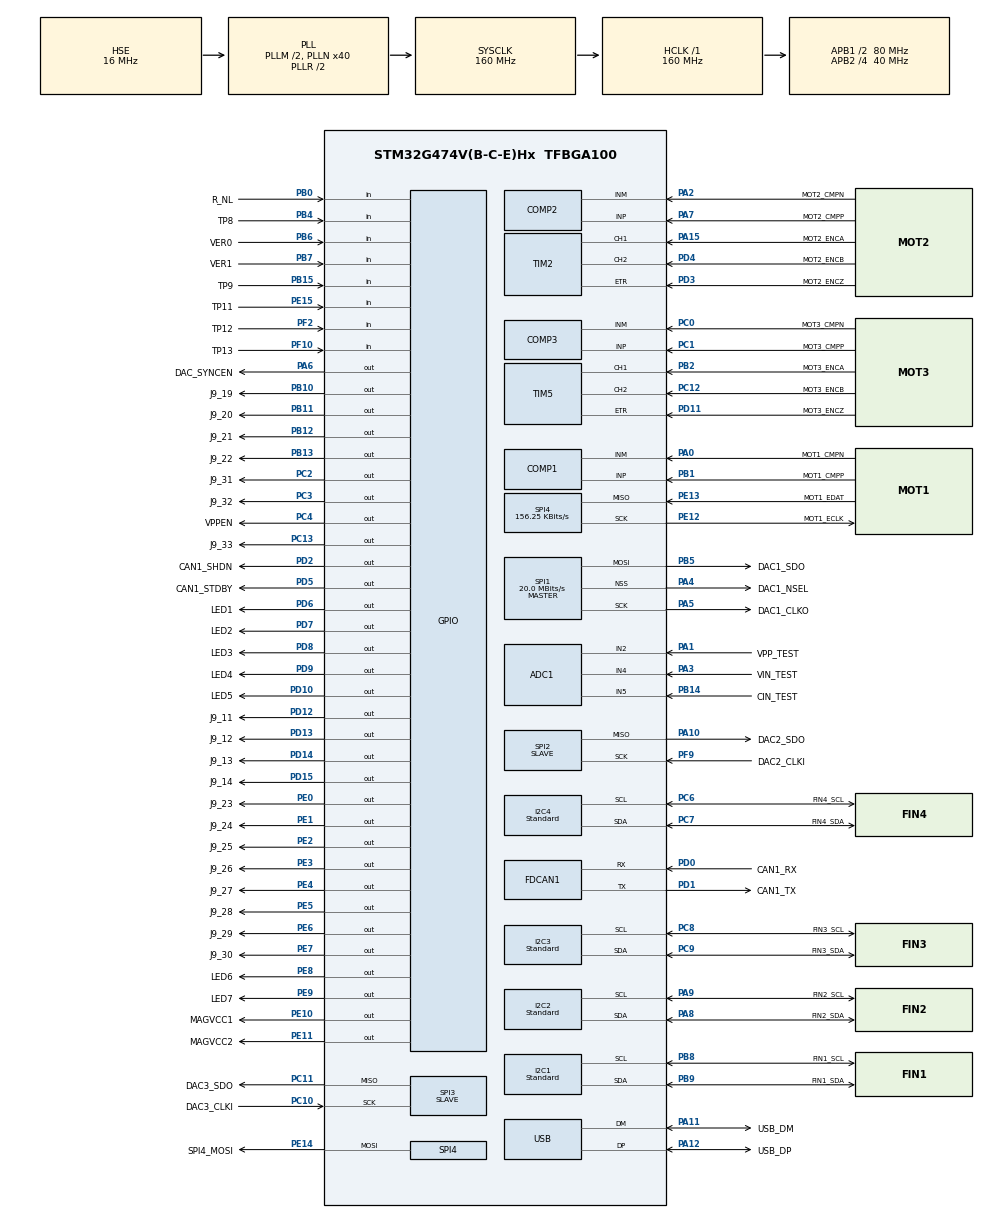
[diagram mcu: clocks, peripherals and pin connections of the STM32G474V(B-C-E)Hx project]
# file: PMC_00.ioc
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Dma.SPI3_TX.2.MemInc=DMA_MINC_ENABLE
Dma.I2C3_TX.8.PeriphInc=DMA_PINC_DISABLE
Dma.I2C2_TX.6.PeriphInc=DMA_PINC_DISABLE
PD12.GPIO_Label=J9_11
Dma.SPI1_TX.0.PeriphInc=DMA_PINC_DISABLE
NVIC.I2C1_EV_IRQn=true\:5\:0\:false\:false\:true\:true\:true\:true
VP_ADC1_TempSens_Input.Mode=IN-TempSens
Dma.I2C1_TX.4.PeriphInc=DMA_PINC_DISABLE
PA10.GPIO_PuPd=GPIO_PULLUP
COMP1.Hysteresis=COMP_HYSTERESIS_10MV
PF10.GPIO_PuPd=GPIO_PULLDOWN
ADC1.SamplingTime-12\#ChannelRegularConversion=ADC_SAMPLETIME_640CYCLES_5
NVIC.I2C4_EV_IRQn=true\:5\:0\:false\:false\:true\:true\:true\:true
NVIC.DMA1_Channel3_IRQn=true\:5\:0\:false\:false\:true\:false\:false\:true
FREERTOS.configENABLE_FPU=1
FREERTOS.INCLUDE_pcTaskGetTaskName=1
ADC1.Channel-5\#ChannelRegularConversion=ADC_CHANNEL_5
PA4.Mode=NSS_Signal_Hard_Output
Dma.I2C3_RX.7.Priority=DMA_PRIORITY_LOW
ADC1.Rank-11\#ChannelRegularConversion=11
SPI1.Direction=SPI_DIRECTION_2LINES
Dma.I2C2_RX.5.Polarity=HAL_DMAMUX_REQ_GEN_RISING
Dma.ADC1.11.Priority=DMA_PRIORITY_HIGH
I2C2.I2C_Speed_Mode=I2C_Standard
RCC.APB2TimFreq_Value=80000000
Dma.SPI3_TX.2.PeriphDataAlignment=DMA_PDATAALIGN_HALFWORD
PB6.Signal=GPIO_Input
Dma.I2C2_RX.5.SyncRequestNumber=1
PC7.Signal=I2C4_SDA
SPI1.CalculateBaudRate=20.0 MBits/s
PD0.Signal=FDCAN1_RX
PD8.Signal=GPIO_Output
PE1.Signal=GPIO_Output
FREERTOS.configMINIMAL_STACK_SIZE=512
Dma.I2C1_RX.3.Mode=DMA_NORMAL
VREF+.Signal=VREFBUF_OUT
PB3.Mode=Trace_Asynchronous_SW
RCC.ADC12Freq_Value=160000000
RCC.RTCClockSelection=RCC_RTCCLKSOURCE_LSE
PD1.GPIO_Label=CAN1_TX
PB12.GPIO_Label=J9_21
Dma.I2C2_TX.6.Mode=DMA_NORMAL
Dma.I2C3_TX.8.MemInc=DMA_MINC_ENABLE
PC4.GPIO_Label=VPPEN
Dma.I2C2_TX.6.Instance=DMA1_Channel7
PD1.GPIO_Speed=GPIO_SPEED_FREQ_VERY_HIGH
PE9.Signal=GPIO_Output
NVIC.DMA2_Channel4_IRQn=true\:5\:0\:false\:false\:true\:true\:false\:true
PB14.Mode=IN5-Single-Ended
PB1.GPIO_Label=MOT1_CMPP
NVIC.TIM2_IRQn=true\:5\:0\:false\:false\:true\:false\:true\:true
SPI1.DataSize=SPI_DATASIZE_16BIT
PE4.GPIO_Label=J9_27
PC9.Mode=I2C
PA8.Signal=I2C2_SDA
PE13.Mode=Full_Duplex_Master
Dma.SPI1_TX.0.RequestNumber=1
NVIC.DMA2_Channel3_IRQn=true\:5\:0\:false\:false\:true\:false\:false\:true
Dma.I2C4_TX.10.Instance=DMA2_Channel3
Dma.ADC1.11.PeriphInc=DMA_PINC_DISABLE
Dma.SPI3_TX.2.Direction=DMA_MEMORY_TO_PERIPH
Dma.SPI1_TX.0.Polarity=HAL_DMAMUX_REQ_GEN_RISING
Dma.I2C3_TX.8.SyncSignalID=NONE
PA0.Signal=COMP1_INM
Dma.I2C4_RX.9.PeriphDataAlignment=DMA_PDATAALIGN_BYTE
Dma.SPI1_TX.0.Mode=DMA_CIRCULAR
ADC1.OffsetNumber-5\#ChannelRegularConversion=ADC_OFFSET_NONE
Mcu.Package=TFBGA100
PB9.Signal=I2C1_SDA
PB1.Signal=COMP1_INP
SPI2.Mode=SPI_MODE_SLAVE
Dma.I2C1_RX.3.SignalID=NONE
SPI3.Mode=SPI_MODE_SLAVE
PD12.Signal=GPIO_Output
PA10.Signal=SPI2_MISO
VP_RTC_VS_RTC_Calendar.Mode=RTC_Calendar
PE12.GPIO_Label=MOT1_ECLK
Dma.ADC1.11.SyncSignalID=NONE
Dma.SPI2_TX.1.Instance=DMA1_Channel2
PC11.Mode=TX_Only_Simplex_Unidirect_Slave
PC8.GPIO_Speed=GPIO_SPEED_FREQ_VERY_HIGH
PE12.GPIO_Speed=GPIO_SPEED_FREQ_VERY_HIGH
Dma.I2C3_RX.7.MemInc=DMA_MINC_ENABLE
PB5.GPIO_Speed=GPIO_SPEED_FREQ_VERY_HIGH
Dma.ADC1.11.SyncEnable=DISABLE
PE8.GPIO_Speed=GPIO_SPEED_FREQ_HIGH
RCC.APB2CLKDivider=RCC_HCLK_DIV4
FDCAN1.DataTimeSeg2=5
FDCAN1.DataTimeSeg1=3
RCC.APB1TimFreq_Value=160000000
PD5.GPIO_Speed=GPIO_SPEED_FREQ_HIGH
NVIC.DMA1_Channel4_IRQn=true\:5\:0\:false\:false\:true\:false\:false\:true
PA4.GPIO_Label=DAC1_NSEL
PA8.GPIO_Speed=GPIO_SPEED_FREQ_VERY_HIGH
ADC1.EOCSelection=ADC_EOC_SEQ_CONV
PD15.Signal=GPIO_Output
PF1-OSC_OUT.Signal=RCC_OSC_OUT
RCC.HSI48_VALUE=48000000
ADC1.Rank-4\#ChannelRegularConversion=4
Dma.I2C1_RX.3.MemDataAlignment=DMA_MDATAALIGN_BYTE
PA5.Mode=TX_Only_Simplex_Unidirect_Master
PE12.Mode=Full_Duplex_Master
Dma.I2C1_TX.4.Priority=DMA_PRIORITY_LOW
PB8-BOOT0.Mode=I2C
I2C4.I2C_Speed_Mode=I2C_Standard
FREERTOS.Tasks01=Main,24,1024,MainTask,Default,NULL,Dynamic,NULL,NULL
Dma.I2C3_TX.8.SyncRequestNumber=1
PD9.PinState=GPIO_PIN_SET
PC13.Signal=GPIO_Output
Dma.Request11=ADC1
Dma.Request10=I2C4_TX
FDCAN1.ProtocolException=ENABLE
PD3.Signal=S_TIM2_ETR
Dma.I2C2_TX.6.SignalID=NONE
PC2.Signal=GPIO_Output
PC14-OSC32_IN.Signal=RCC_OSC32_IN
Dma.I2C4_RX.9.SyncSignalID=NONE
PD10.Signal=GPIO_Output
PA3.Mode=IN4-Single-Ended
Dma.I2C3_TX.8.RequestNumber=1
Dma.I2C3_TX.8.EventEnable=DISABLE
PA8.GPIO_Label=FIN2_SDA
Dma.I2C3_RX.7.EventEnable=DISABLE
PE8.GPIO_Label=LED6
NVIC.I2C2_ER_IRQn=true\:5\:0\:false\:false\:true\:true\:true\:true
Dma.I2C4_TX.10.Direction=DMA_MEMORY_TO_PERIPH
SPI4.NSSPMode=SPI_NSS_PULSE_DISABLE
PB14.Signal=ADC1_IN5
PA5.Signal=SPI1_SCK
Dma.I2C2_RX.5.SyncPolarity=HAL_DMAMUX_SYNC_NO_EVENT
PB8-BOOT0.Signal=I2C1_SCL
PF10.GPIO_Mode=GPIO_MODE_INPUT
ADC1.Rank-12\#ChannelRegularConversion=12
PE1.GPIO_Label=J9_24
PD1.Mode=FDCAN_Activate
Dma.I2C3_TX.8.Instance=DMA2_Channel1
Dma.I2C2_TX.6.MemInc=DMA_MINC_ENABLE
FDCAN1.AutoRetransmission=ENABLE
NVIC.SPI1_IRQn=true\:5\:0\:false\:false\:true\:true\:true\:true
RCC.ADC345Freq_Value=160000000
PE14.Signal=SPI4_MOSI
Dma.SPI2_TX.1.SignalID=NONE
PB4.GPIO_Label=TP8
Dma.SPI2_TX.1.EventEnable=DISABLE
PB15.GPIO_Label=TP9
SPI1.Mode=SPI_MODE_MASTER
PD4.GPIO_Speed=GPIO_SPEED_FREQ_VERY_HIGH
PF1-OSC_OUT.GPIO_Label=OSC_OUT
PA1.GPIO_Label=VPP_TEST
ADC1.Rank-9\#ChannelRegularConversion=9
ADC1.OffsetNumber-12\#ChannelRegularConversion=ADC_OFFSET_NONE
Dma.SPI3_TX.2.SyncEnable=DISABLE
ADC1.ExternalTrigConv=ADC_EXTERNALTRIG_T7_TRGO
PC7.GPIO_Label=FIN4_SDA
PC8.Mode=I2C
FDCAN1.NominalSyncJumpWidth=2
ADC1.master=1
PA5.GPIO_Label=DAC1_CLKO
PB5.GPIO_PuPd=GPIO_PULLUP
PE5.GPIO_Label=J9_28
PC12.GPIO_Label=MOT3_ENCB
ProjectManager.HeapSize=0x800
PB1.Mode=INP
Dma.I2C2_RX.5.MemDataAlignment=DMA_MDATAALIGN_BYTE
PD8.GPIO_Speed=GPIO_SPEED_FREQ_HIGH
NVIC.PriorityGroup=NVIC_PRIORITYGROUP_4
NVIC.I2C3_ER_IRQn=true\:5\:0\:false\:false\:true\:true\:true\:true
USB_DEVICE.APP_RX_DATA_SIZE=4
PE3.Signal=GPIO_Output
Dma.I2C2_RX.5.SyncSignalID=NONE
ADC1.SamplingTime-9\#ChannelRegularConversion=ADC_SAMPLETIME_640CYCLES_5
PD2.Signal=GPIO_Output
Dma.ADC1.11.RequestNumber=1
ADC1.Rank-5\#ChannelRegularConversion=5
PC1.Mode=INP
Mcu.Family=STM32G4
USB_DEVICE.CLASS_NAME_FS=CDC
Dma.SPI1_TX.0.EventEnable=DISABLE
ADC1.OffsetNumber-7\#ChannelRegularConversion=ADC_OFFSET_NONE
Dma.SPI2_TX.1.SyncSignalID=NONE
ADC1.Overrun=ADC_OVR_DATA_OVERWRITTEN
ADC1.ContinuousConvMode=DISABLE
VP_FMAC_VS_FMAC.Mode=FMAC_Activate
PE11.GPIO_Label=MAGVCC2
Dma.ADC1.11.SyncPolarity=HAL_DMAMUX_SYNC_NO_EVENT
Dma.I2C4_RX.9.Direction=DMA_PERIPH_TO_MEMORY
PB2.GPIO_Speed=GPIO_SPEED_FREQ_VERY_HIGH
ADC1.OffsetNumber-4\#ChannelRegularConversion=ADC_OFFSET_NONE
PA0.GPIO_Label=MOT1_CMPN
PD9.GPIO_Speed=GPIO_SPEED_FREQ_HIGH
PD0.GPIO_Label=CAN1_RX
PA11.Mode=Device
Dma.I2C4_TX.10.SyncRequestNumber=1
PF9.GPIO_Speed=GPIO_SPEED_FREQ_VERY_HIGH
Dma.SPI1_TX.0.SyncRequestNumber=1
PB13.GPIO_Label=J9_22
Dma.SPI3_TX.2.Mode=DMA_CIRCULAR
Dma.I2C4_RX.9.SyncPolarity=HAL_DMAMUX_SYNC_NO_EVENT
PB15.Signal=GPIO_Input
FREERTOS.configUSE_TASK_NOTIFICATIONS=1
VP_RTC_VS_RTC_Alarm_B_Intern.Mode=Alarm B
PD13.Signal=GPIO_Output
Dma.SPI3_TX.2.SignalID=NONE
PA15.GPIO_Label=MOT2_ENCA
PC11.GPIO_PuPd=GPIO_PULLUP
SPI3.CLKPolarity=SPI_POLARITY_HIGH
Dma.SPI2_TX.1.Polarity=HAL_DMAMUX_REQ_GEN_RISING
ADC1.Channel-3\#ChannelRegularConversion=ADC_CHANNEL_4
Dma.I2C2_RX.5.MemInc=DMA_MINC_ENABLE
Dma.I2C4_TX.10.Polarity=HAL_DMAMUX_REQ_GEN_RISING
USB_DEVICE.USBD_LPM_ENABLED=0
FREERTOS.configQUEUE_REGISTRY_SIZE=16
NVIC.DMA2_Channel2_IRQn=true\:5\:0\:false\:false\:true\:false\:false\:true
RCC.HSE_VALUE=16000000
PA4.GPIO_PuPd=GPIO_PULLUP
PA4.GPIO_Speed=GPIO_SPEED_FREQ_VERY_HIGH
PC4.GPIO_Speed=GPIO_SPEED_FREQ_HIGH
PF9.Mode=TX_Only_Simplex_Unidirect_Slave
PC14-OSC32_IN.Mode=LSE-External-Oscillator
Dma.I2C3_RX.7.SyncPolarity=HAL_DMAMUX_SYNC_NO_EVENT
PA14.Mode=Trace_Asynchronous_SW
PB5.Mode=TX_Only_Simplex_Unidirect_Master
PC11.GPIO_Label=DAC3_SDO
VP_SYS_VS_DBSignals.Mode=DisableDeadBatterySignals
PD6.PinState=GPIO_PIN_RESET
PB7.Signal=GPIO_Input
Dma.I2C2_RX.5.Instance=DMA1_Channel6
FREERTOS.INCLUDE_vTaskCleanUpResources=1
ADC1.OffsetNumber-11\#ChannelRegularConversion=ADC_OFFSET_NONE
PD10.GPIO_Speed=GPIO_SPEED_FREQ_HIGH
TIM7.TIM_MasterOutputTrigger=TIM_TRGO_UPDATE
Dma.I2C3_RX.7.Polarity=HAL_DMAMUX_REQ_GEN_RISING
PB7.GPIO_Label=VER1
Dma.I2C1_RX.3.PeriphInc=DMA_PINC_DISABLE
PD13.GPIO_Label=J9_12
Dma.I2C3_TX.8.Polarity=HAL_DMAMUX_REQ_GEN_RISING
PA6.Signal=GPIO_Output
Dma.SPI2_TX.1.RequestNumber=1
PB15.GPIO_PuPd=GPIO_PULLDOWN
PD5.GPIO_Label=CAN1_STDBY
Dma.I2C3_RX.7.RequestNumber=1
PA15.Signal=S_TIM2_CH1
PB8-BOOT0.GPIO_Label=FIN1_SCL
Dma.I2C4_RX.9.SyncRequestNumber=1
NVIC.SPI3_IRQn=true\:5\:0\:false\:false\:true\:true\:true\:true
PA10.GPIO_Speed=GPIO_SPEED_FREQ_VERY_HIGH
I2C3.Timing=0x10909CEC
PB5.GPIO_Label=DAC1_SDO
Dma.Request2=SPI3_TX
Dma.Request1=SPI2_TX
Dma.Request4=I2C1_TX
Dma.Request3=I2C1_RX
FREERTOS.configUSE_TICK_HOOK=0
SH.S_TIM5_CH1.0=TIM5_CH1,Encoder_Interface_w_index
Dma.Request6=I2C2_TX
Dma.Request5=I2C2_RX
Dma.Request8=I2C3_TX
Dma.I2C1_RX.3.EventEnable=DISABLE
PD3.GPIO_Label=MOT2_ENCZ
PC5.Signal=SYS_WKUP5
Dma.Request7=I2C3_RX
RCC.CK48CLockSelection=RCC_USBCLKSOURCE_HSI48
PE7.Signal=GPIO_Output
PF1-OSC_OUT.Mode=HSE-External-Oscillator
PD6.Signal=GPIO_Output
ADC1.Rank-6\#ChannelRegularConversion=6
Dma.Request0=SPI1_TX
ADC1.SamplingTime-8\#ChannelRegularConversion=ADC_SAMPLETIME_640CYCLES_5
PE9.PinState=GPIO_PIN_SET
PE2.GPIO_Label=J9_25
PB9.GPIO_FM9=__NULL
Dma.I2C4_RX.9.RequestNumber=1
PB4.Signal=GPIO_Input
PA3.Signal=ADC1_IN4
NVIC.FDCAN1_IT0_IRQn=true\:5\:0\:false\:false\:true\:true\:true\:true
SH.S_TIM2_CH1.0=TIM2_CH1,Encoder_Interface_w_index
PD15.GPIO_Label=J9_14
PA10.Mode=TX_Only_Simplex_Unidirect_Slave
ADC1.Rank-10\#ChannelRegularConversion=10
PC9.GPIO_Label=FIN3_SDA
SPI4.DataSize=SPI_DATASIZE_16BIT
Dma.SPI3_TX.2.Polarity=HAL_DMAMUX_REQ_GEN_RISING
ADC1.Rank-8\#ChannelRegularConversion=8
PC11.Signal=SPI3_MISO
PC8.Signal=I2C3_SCL
PC10.Mode=TX_Only_Simplex_Unidirect_Slave
VP_ADC1_Vbat_Input.Mode=IN-Vbat
PE14.GPIO_Label=SPI4_MOSI
PD9.Signal=GPIO_Output
Dma.I2C3_TX.8.SignalID=NONE
PA12.GPIO_Label=USB_DP
PD8.GPIO_Label=LED3
Dma.I2C3_RX.7.SyncSignalID=NONE
PA13.Signal=SYS_JTMS-SWDIO
FREERTOS.configUSE_IDLE_HOOK=0
PA9.Mode=I2C
PB10.GPIO_Label=J9_19
Dma.ADC1.11.Mode=DMA_CIRCULAR
FREERTOS.configUSE_TRACE_FACILITY=1
Dma.SPI1_TX.0.PeriphDataAlignment=DMA_PDATAALIGN_HALFWORD
Dma.SPI1_TX.0.Direction=DMA_MEMORY_TO_PERIPH
Dma.SPI2_TX.1.SyncPolarity=HAL_DMAMUX_SYNC_NO_EVENT
PB9.Mode=I2C
Dma.ADC1.11.EventEnable=DISABLE
Dma.I2C2_RX.5.PeriphInc=DMA_PINC_DISABLE
RCC.USBFreq_Value=48000000
PF9.GPIO_Label=DAC2_CLKI
PD10.GPIO_Label=LED5
PA1.Signal=ADC1_IN2
TIM7.Prescaler=83
board=custom
SH.S_TIM5_ETR.0=TIM5_ETR,Encoder_Interface_w_index
PC7.GPIO_Speed=GPIO_SPEED_FREQ_VERY_HIGH
Dma.SPI2_TX.1.Direction=DMA_MEMORY_TO_PERIPH
Dma.I2C4_RX.9.Mode=DMA_NORMAL
RCC.VCOOutputFreq_Value=320000000
SYS.VoltageScaling=SYSCFG_VREFBUF_VOLTAGE_SCALE1
ADC1.Channel-12\#ChannelRegularConversion=ADC_CHANNEL_VREFINT
Dma.I2C4_RX.9.SignalID=NONE
Dma.ADC1.11.SyncRequestNumber=1
Dma.ADC1.11.Instance=DMA2_Channel4
PC1.GPIO_Label=MOT3_CMPP
PB8-BOOT0.GPIO_FM8=__NULL
Dma.I2C1_TX.4.SyncEnable=DISABLE
Dma.I2C1_TX.4.Instance=DMA1_Channel5
Dma.I2C4_TX.10.SignalID=NONE
ADC1.NbrOfConversion=12
ADC1.OffsetNumber-2\#ChannelRegularConversion=ADC_OFFSET_NONE
PE0.Signal=GPIO_Output
RTC.Alarm-Alarm\ A=RTC_ALARM_A
PE7.GPIO_Label=J9_30
PE12.Signal=SPI4_SCK
Dma.I2C1_RX.3.Instance=DMA1_Channel4
RCC.SYSCLKFreq_VALUE=160000000
SH.S_TIM2_ETR.0=TIM2_ETR,Encoder_Interface_w_index
ADC1.Rank-3\#ChannelRegularConversion=3
ADC1.SamplingTime-3\#ChannelRegularConversion=ADC_SAMPLETIME_640CYCLES_5
Dma.I2C4_RX.9.Polarity=HAL_DMAMUX_REQ_GEN_RISING
PA15.GPIO_Speed=GPIO_SPEED_FREQ_VERY_HIGH
USB_DEVICE.APP_TX_DATA_SIZE=4
PE15.GPIO_PuPd=GPIO_PULLDOWN
PB2.GPIO_Label=MOT3_ENCA
Dma.SPI1_TX.0.MemDataAlignment=DMA_MDATAALIGN_HALFWORD
Dma.SPI1_TX.0.Priority=DMA_PRIORITY_HIGH
COMP3.Hysteresis=COMP_HYSTERESIS_10MV
FREERTOS.INCLUDE_xTaskGetHandle=1
NVIC.I2C2_EV_IRQn=true\:5\:0\:false\:false\:true\:true\:true\:true
RCC.HSI_VALUE=16000000
Dma.I2C1_RX.3.MemInc=DMA_MINC_ENABLE
RCC.PLLQ=RCC_PLLQ_DIV8
RCC.PLLM=RCC_PLLM_DIV2
RCC.PLLN=40
PA9.GPIO_Speed=GPIO_SPEED_FREQ_VERY_HIGH
PA2.Mode=INM
NVIC.DMA1_Channel7_IRQn=true\:5\:0\:false\:false\:true\:false\:false\:true
COMP2.TriggerMode=COMP_TRIGGERMODE_IT_RISING
PD6.GPIO_Speed=GPIO_SPEED_FREQ_HIGH
PC12.GPIO_Speed=GPIO_SPEED_FREQ_VERY_HIGH
VP_CRC_VS_CRC.Mode=CRC_Activate
PB12.Signal=GPIO_Output
PA3.GPIO_Label=VIN_TEST
Dma.I2C3_TX.8.SyncEnable=DISABLE
Dma.I2C3_RX.7.MemDataAlignment=DMA_MDATAALIGN_BYTE
NVIC.ADC1_2_IRQn=true\:5\:0\:false\:false\:true\:false\:true\:true
RTC.Alarm_B-Alarm\ B=RTC_ALARM_B
PE15.GPIO_Mode=GPIO_MODE_INPUT
TIM7.PeriodNoDither=4999
PB15.GPIO_Mode=GPIO_MODE_INPUT
PE14.GPIO_Speed=GPIO_SPEED_FREQ_VERY_HIGH
SPI3.Direction=SPI_DIRECTION_2LINES
SPI4.VirtualType=VM_MASTER
SPI3.VirtualType=VM_SLAVE
I2C1.I2C_Speed_Mode=I2C_Standard
SPI1.VirtualType=VM_MASTER
SPI2.VirtualType=VM_SLAVE
ADC1.SamplingTime-6\#ChannelRegularConversion=ADC_SAMPLETIME_640CYCLES_5
PC12.Signal=S_TIM5_CH2
PB14.GPIO_Label=CIN_TEST
PA14.GPIO_Label=SWCLK
ADC1.OffsetNumber-10\#ChannelRegularConversion=ADC_OFFSET_NONE
Dma.I2C2_RX.5.Mode=DMA_NORMAL
PC6.GPIO_Label=FIN4_SCL
VP_RTC_VS_RTC_Activate.Mode=RTC_Enabled
Dma.I2C2_TX.6.SyncRequestNumber=1
PB6.GPIO_Label=VER0
PA6.GPIO_Label=DAC_SYNCEN
PC5.Mode=SYS_WakeUp4
Dma.I2C2_TX.6.SyncSignalID=NONE
PB13.Signal=GPIO_Output
PD3.GPIO_Speed=GPIO_SPEED_FREQ_VERY_HIGH
PD6.GPIO_Label=LED1
PC15-OSC32_OUT.GPIO_Label=OSC32_OUT
PE6.GPIO_Label=J9_29
ADC1.Channel-8\#ChannelRegularConversion=ADC_CHANNEL_TEMPSENSOR_ADC1
Dma.I2C1_RX.3.Priority=DMA_PRIORITY_MEDIUM
RCC.SYSCLKSource=RCC_SYSCLKSOURCE_PLLCLK
Dma.ADC1.11.MemInc=DMA_MINC_ENABLE
Dma.I2C2_TX.6.EventEnable=DISABLE
Dma.I2C4_TX.10.Priority=DMA_PRIORITY_MEDIUM
NVIC.SPI4_IRQn=true\:5\:0\:false\:false\:true\:true\:true\:true
Dma.SPI3_TX.2.SyncRequestNumber=1
NVIC.TIM5_IRQn=true\:5\:0\:false\:false\:true\:false\:true\:true
Dma.I2C4_TX.10.MemInc=DMA_MINC_ENABLE
I2C4.Timing=0x10909CEC
PD4.Signal=S_TIM2_CH2
ADC1.Channel-2\#ChannelRegularConversion=ADC_CHANNEL_2
PC3.Signal=GPIO_Output
PE5.Signal=GPIO_Output
PF10.GPIO_Label=TP13
PF0-OSC_IN.GPIO_Label=OSC_IN
PB2.Signal=S_TIM5_CH1
ADC1.OffsetNumber-9\#ChannelRegularConversion=ADC_OFFSET_NONE
VP_ADC1_Vref_Input.Mode=IN-Vrefint
PA5.GPIO_PuPd=GPIO_PULLUP
FDCAN1.NominalPrescaler=2
PA0.Mode=INM
NVIC.I2C4_ER_IRQn=true\:5\:0\:false\:false\:true\:false\:true\:true
PC11.GPIO_Speed=GPIO_SPEED_FREQ_VERY_HIGH
PE2.Signal=GPIO_Output
Dma.I2C3_RX.7.SignalID=NONE
SPI1.VirtualNSS=VM_NSSHARD
NVIC.I2C1_ER_IRQn=true\:5\:0\:false\:false\:true\:true\:true\:true
PE10.Signal=GPIO_Output
Dma.SPI1_TX.0.SyncEnable=DISABLE
Dma.ADC1.11.SignalID=NONE
NVIC.USB_LP_IRQn=true\:5\:0\:true\:false\:true\:false\:false\:true
Dma.I2C4_TX.10.SyncPolarity=HAL_DMAMUX_SYNC_NO_EVENT
Dma.I2C1_RX.3.SyncEnable=DISABLE
PA6.GPIO_Speed=GPIO_SPEED_FREQ_HIGH
Dma.SPI2_TX.1.SyncRequestNumber=1
PE10.GPIO_Label=MAGVCC1
Dma.I2C2_TX.6.SyncEnable=DISABLE
PC6.GPIO_Speed=GPIO_SPEED_FREQ_VERY_HIGH
Dma.I2C3_TX.8.Mode=DMA_NORMAL
Dma.I2C2_TX.6.Direction=DMA_MEMORY_TO_PERIPH
Dma.I2C3_TX.8.SyncPolarity=HAL_DMAMUX_SYNC_NO_EVENT
ADC1.Channel-10\#ChannelRegularConversion=ADC_CHANNEL_VBAT
NVIC.DMA1_Channel6_IRQn=true\:5\:0\:false\:false\:true\:false\:false\:true
Dma.SPI2_TX.1.MemInc=DMA_MINC_ENABLE
VREF+.Mode=InternalMode
Dma.I2C4_TX.10.SyncEnable=DISABLE
NVIC.COMP1_2_3_IRQn=true\:5\:0\:false\:false\:true\:false\:false\:true
PD9.GPIO_Label=LED4
Dma.I2C2_TX.6.Priority=DMA_PRIORITY_MEDIUM
Dma.I2C1_TX.4.SignalID=NONE
Dma.Request9=I2C4_RX
PE11.GPIO_Speed=GPIO_SPEED_FREQ_HIGH
Dma.ADC1.11.MemDataAlignment=DMA_MDATAALIGN_HALFWORD
FREERTOS.INCLUDE_xTaskGetCurrentTaskHandle=1
PA9.GPIO_Label=FIN2_SCL
Dma.SPI3_TX.2.EventEnable=DISABLE
PC6.Signal=I2C4_SCL
PB11.GPIO_Label=J9_20
PD7.Signal=GPIO_Output
PD1.Signal=FDCAN1_TX
PA11.GPIO_Label=USB_DM
Dma.I2C2_RX.5.EventEnable=DISABLE
PC0.Signal=COMP3_INM
RCC.APB1CLKDivider=RCC_HCLK_DIV2
Dma.ADC1.11.Direction=DMA_PERIPH_TO_MEMORY
PD0.GPIO_Speed=GPIO_SPEED_FREQ_VERY_HIGH
ADC1.Channel-7\#ChannelRegularConversion=ADC_CHANNEL_TEMPSENSOR_ADC1
NVIC.DMA1_Channel8_IRQn=true\:5\:0\:false\:false\:true\:false\:false\:true
PF2.GPIO_Mode=GPIO_MODE_INPUT
ADC1.OffsetNumber-8\#ChannelRegularConversion=ADC_OFFSET_NONE
PC6.Mode=I2C
PD11.GPIO_Speed=GPIO_SPEED_FREQ_VERY_HIGH
PA9.Signal=I2C2_SCL
I2C1.Timing=0x10909CEC
Dma.SPI1_TX.0.SyncPolarity=HAL_DMAMUX_SYNC_NO_EVENT
PB4.GPIO_PuPd=GPIO_PULLDOWN
PE9.GPIO_Label=LED7
Dma.I2C3_TX.8.MemDataAlignment=DMA_MDATAALIGN_BYTE
PB10.Signal=GPIO_Output
PA1.Mode=IN2-Single-Ended
Dma.I2C2_TX.6.Polarity=HAL_DMAMUX_REQ_GEN_RISING
PE15.Signal=GPIO_Input
Dma.SPI2_TX.1.PeriphDataAlignment=DMA_PDATAALIGN_HALFWORD
PE8.Signal=GPIO_Output
Dma.SPI2_TX.1.Priority=DMA_PRIORITY_VERY_HIGH
Dma.I2C4_TX.10.PeriphInc=DMA_PINC_DISABLE
Dma.SPI1_TX.0.Instance=DMA1_Channel1
Dma.I2C3_RX.7.PeriphInc=DMA_PINC_DISABLE
FREERTOS.INCLUDE_xEventGroupSetBitFromISR=1
ADC1.DMAContinuousRequests=ENABLE
ADC1.SamplingTime-10\#ChannelRegularConversion=ADC_SAMPLETIME_640CYCLES_5
PA13.Mode=Trace_Asynchronous_SW
Dma.I2C1_RX.3.SyncRequestNumber=1
FDCAN1.DataPrescaler=2
PA4.Signal=SPI1_NSS
ADC1.SamplingTime-1\#ChannelRegularConversion=ADC_SAMPLETIME_640CYCLES_5
PB5.Signal=SPI1_MOSI
Dma.I2C3_TX.8.Direction=DMA_MEMORY_TO_PERIPH
PE13.GPIO_Label=MOT1_EDAT
Dma.I2C3_RX.7.PeriphDataAlignment=DMA_PDATAALIGN_BYTE
PD11.Signal=S_TIM5_ETR
ADC1.Rank-1\#ChannelRegularConversion=1
PA11.Signal=USB_DM
NVIC.DMA2_Channel1_IRQn=true\:5\:0\:false\:false\:true\:false\:false\:true
Dma.SPI3_TX.2.PeriphInc=DMA_PINC_DISABLE
Dma.I2C2_RX.5.SignalID=NONE
ADC1.SamplingTime-5\#ChannelRegularConversion=ADC_SAMPLETIME_640CYCLES_5
Dma.I2C1_TX.4.RequestNumber=1
PF9.Signal=SPI2_SCK
Dma.I2C3_RX.7.Instance=DMA1_Channel8
PC9.GPIO_Speed=GPIO_SPEED_FREQ_VERY_HIGH
PC3.GPIO_Label=J9_32
PA8.Mode=I2C
SPI2.DataSize=SPI_DATASIZE_16BIT
Dma.I2C3_TX.8.PeriphDataAlignment=DMA_PDATAALIGN_BYTE
NVIC.DMA1_Channel1_IRQn=true\:5\:0\:false\:false\:true\:false\:false\:true
PF0-OSC_IN.Signal=RCC_OSC_IN
PB0.Signal=GPIO_Input
Dma.SPI2_TX.1.MemDataAlignment=DMA_MDATAALIGN_HALFWORD
PC1.Signal=COMP3_INP
PD2.GPIO_Label=CAN1_SHDN
I2C3.I2C_Speed_Mode=I2C_Standard
Dma.I2C3_RX.7.Direction=DMA_PERIPH_TO_MEMORY
Dma.SPI1_TX.0.MemInc=DMA_MINC_ENABLE
PE8.PinState=GPIO_PIN_SET
Dma.I2C1_RX.3.SyncSignalID=NONE
RCC.CortexFreq_Value=160000000
NVIC.DMA1_Channel5_IRQn=true\:5\:0\:false\:false\:true\:false\:false\:true
Dma.I2C1_RX.3.Direction=DMA_PERIPH_TO_MEMORY
ADC1.GainCompensation=4096
Dma.SPI3_TX.2.Instance=DMA1_Channel3
Dma.I2C2_RX.5.Direction=DMA_PERIPH_TO_MEMORY
FDCAN1.DataSyncJumpWidth=2
PC10.Signal=SPI3_SCK
SPI4.Direction=SPI_DIRECTION_2LINES
I2C2.Timing=0x10909CEC
SH.S_TIM5_CH2.0=TIM5_CH2,Encoder_Interface_w_index
Dma.SPI2_TX.1.PeriphInc=DMA_PINC_DISABLE
PC0.GPIO_Label=MOT3_CMPN
PE9.GPIO_Speed=GPIO_SPEED_FREQ_HIGH
PD2.GPIO_Speed=GPIO_SPEED_FREQ_HIGH
PB0.GPIO_Label=R_NL
PC10.GPIO_Speed=GPIO_SPEED_FREQ_VERY_HIGH
PC13.GPIO_Label=J9_33
PB11.Signal=GPIO_Output
Dma.SPI3_TX.2.SyncSignalID=NONE
VP_RTC_VS_RTC_Alarm_A_Intern.Mode=Alarm A
ProjectManager.StackSize=0x800
VP_FREERTOS_VS_CMSIS_V2.Mode=CMSIS_V2
Dma.I2C2_RX.5.Priority=DMA_PRIORITY_LOW
Dma.I2C2_RX.5.RequestNumber=1
Dma.I2C4_RX.9.MemInc=DMA_MINC_ENABLE
VP_TIM7_VS_ClockSourceINT.Mode=Enable_Timer
Dma.I2C1_TX.4.PeriphDataAlignment=DMA_PDATAALIGN_BYTE
PA12.Signal=USB_DP
SPI1.CLKPolarity=SPI_POLARITY_HIGH
SPI2.CLKPolarity=SPI_POLARITY_HIGH
PB4.GPIO_Mode=GPIO_MODE_INPUT
SPI4.Mode=SPI_MODE_MASTER
FREERTOS.configUSE_STATS_FORMATTING_FUNCTIONS=1
Dma.I2C4_RX.9.SyncEnable=DISABLE
PD11.GPIO_Label=MOT3_ENCZ
RCC.HCLKFreq_Value=160000000
Dma.I2C4_RX.9.Priority=DMA_PRIORITY_MEDIUM
PF2.GPIO_PuPd=GPIO_PULLDOWN
SPI4.CLKPolarity=SPI_POLARITY_HIGH
Dma.I2C1_RX.3.Polarity=HAL_DMAMUX_REQ_GEN_RISING
RCC.AHBFreq_Value=160000000
SPI3.DataSize=SPI_DATASIZE_16BIT
Dma.SPI2_TX.1.SyncEnable=DISABLE
Dma.I2C4_RX.9.MemDataAlignment=DMA_MDATAALIGN_BYTE
PD7.GPIO_Speed=GPIO_SPEED_FREQ_HIGH
ADC1.SamplingTime-4\#ChannelRegularConversion=ADC_SAMPLETIME_640CYCLES_5
NVIC.I2C3_EV_IRQn=true\:5\:0\:false\:false\:true\:true\:true\:true
ADC1.Channel-6\#ChannelRegularConversion=ADC_CHANNEL_5
ADC1.Rank-2\#ChannelRegularConversion=2
PE13.Signal=SPI4_MISO
Dma.I2C3_RX.7.SyncEnable=DISABLE
USB_DEVICE.USBD_SELF_POWERED=0
VP_CORDIC_VS_CORDIC.Mode=CORDIC_Activate
PA10.GPIO_Label=DAC2_SDO
Dma.I2C1_TX.4.Polarity=HAL_DMAMUX_REQ_GEN_RISING
NVIC.SPI2_IRQn=true\:5\:0\:false\:false\:true\:true\:true\:true
PE10.GPIO_Speed=GPIO_SPEED_FREQ_HIGH
Dma.I2C2_TX.6.SyncPolarity=HAL_DMAMUX_SYNC_NO_EVENT
Dma.SPI3_TX.2.Priority=DMA_PRIORITY_VERY_HIGH
VREF+.GPIO_Label=VREF
Dma.I2C3_RX.7.SyncRequestNumber=1
Dma.ADC1.11.Polarity=HAL_DMAMUX_REQ_GEN_RISING
PE4.Signal=GPIO_Output
SPI4.BaudRatePrescaler=SPI_BAUDRATEPRESCALER_256
NVIC.FDCAN1_IT1_IRQn=true\:5\:0\:false\:false\:true\:true\:true\:true
FDCAN1.NominalTimeSeg2=5
FREERTOS.configTOTAL_HEAP_SIZE=16384
FDCAN1.NominalTimeSeg1=3
PD7.GPIO_Label=LED2
ADC1.SamplingTime-11\#ChannelRegularConversion=ADC_SAMPLETIME_640CYCLES_5
COMP2.Hysteresis=COMP_HYSTERESIS_10MV
Dma.SPI2_TX.1.Mode=DMA_CIRCULAR
FREERTOS.INCLUDE_xTaskAbortDelay=1
Dma.I2C4_RX.9.Instance=DMA2_Channel2
PA2.GPIO_Label=MOT2_CMPN
ADC1.Channel-11\#ChannelRegularConversion=ADC_CHANNEL_VREFINT
ADC1.OffsetNumber-1\#ChannelRegularConversion=ADC_OFFSET_NONE
Dma.I2C1_TX.4.SyncPolarity=HAL_DMAMUX_SYNC_NO_EVENT
PE0.GPIO_Label=J9_23
Dma.I2C1_TX.4.EventEnable=DISABLE
PB8-BOOT0.GPIO_Speed=GPIO_SPEED_FREQ_VERY_HIGH
PB9.GPIO_Speed=GPIO_SPEED_FREQ_VERY_HIGH
Dma.I2C4_RX.9.EventEnable=DISABLE
Dma.I2C2_RX.5.PeriphDataAlignment=DMA_PDATAALIGN_BYTE
Dma.SPI3_TX.2.RequestNumber=1
PC14-OSC32_IN.GPIO_Label=OSC32_IN
SPI2.Direction=SPI_DIRECTION_2LINES
Dma.SPI1_TX.0.SyncSignalID=NONE
COMP3.TriggerMode=COMP_TRIGGERMODE_IT_RISING
SPI1.BaudRatePrescaler=SPI_BAUDRATEPRESCALER_2
Dma.I2C4_RX.9.PeriphInc=DMA_PINC_DISABLE
PC2.GPIO_Label=J9_31
COMP1.TriggerMode=COMP_TRIGGERMODE_IT_RISING
PB3.GPIO_Label=SWO
RCC.PLLSourceVirtual=RCC_PLLSOURCE_HSE
PC15-OSC32_OUT.Mode=LSE-External-Oscillator
Dma.I2C1_TX.4.MemDataAlignment=DMA_MDATAALIGN_BYTE
PA7.Mode=INP
PB9.GPIO_Label=FIN1_SDA
ADC1.Channel-4\#ChannelRegularConversion=ADC_CHANNEL_4
PC10.GPIO_Label=DAC3_CLKI
USB_DEVICE.VirtualModeFS=Cdc_FS
Dma.I2C4_TX.10.SyncSignalID=NONE
ADC1.OffsetNumber-3\#ChannelRegularConversion=ADC_OFFSET_NONE
PC4.Signal=GPIO_Output
ADC1.DiscontinuousConvMode=ENABLE
Dma.I2C1_RX.3.PeriphDataAlignment=DMA_PDATAALIGN_BYTE
RCC.EXTERNAL_CLOCK_VALUE=12288000
PD5.Signal=GPIO_Output
Dma.I2C2_TX.6.MemDataAlignment=DMA_MDATAALIGN_BYTE
Dma.I2C2_TX.6.PeriphDataAlignment=DMA_PDATAALIGN_BYTE
VP_RNG_VS_RNG.Mode=RNG_Activate
Dma.SPI3_TX.2.SyncPolarity=HAL_DMAMUX_SYNC_NO_EVENT
Dma.I2C2_RX.5.SyncEnable=DISABLE
Dma.I2C4_TX.10.Mode=DMA_NORMAL
ADC1.SamplingTime-2\#ChannelRegularConversion=ADC_SAMPLETIME_640CYCLES_5
PC0.Mode=INM
Dma.SPI1_TX.0.SignalID=NONE
PC8.GPIO_Label=FIN3_SCL
SH.S_TIM2_CH2.0=TIM2_CH2,Encoder_Interface_w_index
PE15.GPIO_Label=TP11
Dma.I2C1_TX.4.Mode=DMA_NORMAL
Dma.I2C1_RX.3.RequestNumber=1
NVIC.DMA1_Channel2_IRQn=true\:5\:0\:false\:false\:true\:false\:false\:true
ProjectManager.TargetToolchain=Makefile
Dma.I2C4_TX.10.EventEnable=DISABLE
VP_USB_DEVICE_VS_USB_DEVICE_CDC_FS.Mode=CDC_FS
ADC1.Channel-1\#ChannelRegularConversion=ADC_CHANNEL_2
Dma.I2C1_TX.4.SyncRequestNumber=1
PF2.Signal=GPIO_Input
PE11.Signal=GPIO_Output
PC15-OSC32_OUT.Signal=RCC_OSC32_OUT
PF0-OSC_IN.Mode=HSE-External-Oscillator
Dma.I2C4_TX.10.PeriphDataAlignment=DMA_PDATAALIGN_BYTE
PD2.PinState=GPIO_PIN_SET
Dma.I2C4_TX.10.RequestNumber=1
Dma.I2C1_TX.4.SyncSignalID=NONE
ADC1.NbrOfDiscConversion=2
RCC.APB2Freq_Value=40000000
PD4.GPIO_Label=MOT2_ENCB
PF10.Signal=GPIO_Input
PE14.Mode=Full_Duplex_Master
Dma.SPI3_TX.2.MemDataAlignment=DMA_MDATAALIGN_HALFWORD
Dma.I2C1_TX.4.MemInc=DMA_MINC_ENABLE
Dma.ADC1.11.PeriphDataAlignment=DMA_PDATAALIGN_HALFWORD
SPI4.CalculateBaudRate=156.25 KBits/s
PD14.GPIO_Label=J9_13
PD5.PinState=GPIO_PIN_SET
PE6.Signal=GPIO_Output
Mcu.Name=STM32G474V(B-C-E)Hx
PD0.Mode=FDCAN_Activate
FREERTOS.INCLUDE_xSemaphoreGetMutexHolder=1
Dma.I2C1_TX.4.Direction=DMA_MEMORY_TO_PERIPH
PA13.GPIO_Label=SWDIO
PA2.Signal=COMP2_INM
ADC1.OffsetNumber-6\#ChannelRegularConversion=ADC_OFFSET_NONE
ADC1.Channel-9\#ChannelRegularConversion=ADC_CHANNEL_VBAT
PD14.Signal=GPIO_Output
PB3.Signal=SYS_JTDO-SWO
PA7.GPIO_Label=MOT2_CMPP
Dma.I2C4_TX.10.MemDataAlignment=DMA_MDATAALIGN_BYTE
PA12.Mode=Device
PC5.GPIO_Label=NPWF
Dma.I2C2_TX.6.RequestNumber=1
PA14.Signal=SYS_JTCK-SWCLK
Dma.I2C3_RX.7.Mode=DMA_NORMAL
PD10.PinState=GPIO_PIN_SET
VP_RTC_VS_RTC_WakeUp_intern.Mode=WakeUp
ADC1.Rank-7\#ChannelRegularConversion=7
PA5.GPIO_Speed=GPIO_SPEED_FREQ_VERY_HIGH
ADC1.NbrOfConversionFlag=1
PE13.GPIO_Speed=GPIO_SPEED_FREQ_VERY_HIGH
Dma.I2C3_TX.8.Priority=DMA_PRIORITY_LOW
Dma.I2C1_RX.3.SyncPolarity=HAL_DMAMUX_SYNC_NO_EVENT
PE3.GPIO_Label=J9_26
PC9.Signal=I2C3_SDA
ADC1.SamplingTime-7\#ChannelRegularConversion=ADC_SAMPLETIME_640CYCLES_5
PC7.Mode=I2C
RCC.APB1Freq_Value=80000000
USB_DEVICE.VirtualMode=Cdc
PA7.Signal=COMP2_INP
PF2.GPIO_Label=TP12

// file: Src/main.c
/* USER CODE BEGIN Header */
/**
  ******************************************************************************
  * @file           : main.c
  * @brief          : Main program body
  ******************************************************************************
  * @attention
  *
  * <h2><center>&copy; Copyright (c) 2020 STMicroelectronics.
  * All rights reserved.</center></h2>
  *
  * This software component is licensed by ST under BSD 3-Clause license,
  * the "License"; You may not use this file except in compliance with the
  * License. You may obtain a copy of the License at:
  *                        opensource.org/licenses/BSD-3-Clause
  *
  ******************************************************************************
  */
/* USER CODE END Header */
#include "main.h"
#include "cmsis_os.h"
#include "adc.h"
#include "comp.h"
#include "cordic.h"
#include "crc.h"
#include "dma.h"
#include "fdcan.h"
#include "fmac.h"
#include "i2c.h"
#include "rng.h"
#include "rtc.h"
#include "spi.h"
#include "tim.h"
#include "usb_device.h"
#include "gpio.h"

void SystemClock_Config(void);
void MX_FREERTOS_Init(void);

int main(void)
{

  /* MCU Configuration--------------------------------------------------------*/

  /* Reset of all peripherals, Initializes the Flash interface and the Systick. */
  HAL_Init();

  /* Configure the system clock */
  SystemClock_Config();

  /* Initialize all configured peripherals */
  MX_GPIO_Init();
  MX_DMA_Init();
  MX_ADC1_Init();
  MX_COMP1_Init();
  MX_COMP2_Init();
  MX_COMP3_Init();
  MX_CORDIC_Init();
  MX_CRC_Init();
  MX_FDCAN1_Init();
  MX_FMAC_Init();
  MX_I2C1_Init();
  MX_I2C2_Init();
  MX_I2C3_Init();
  MX_I2C4_Init();
  MX_RNG_Init();
  MX_RTC_Init();
  MX_SPI1_Init();
  MX_SPI2_Init();
  MX_SPI3_Init();
  MX_SPI4_Init();
  MX_TIM2_Init();
  MX_TIM5_Init();
  MX_USB_Device_Init();
  MX_TIM7_Init();

  /* Init scheduler */
  osKernelInitialize();  /* Call init function for freertos objects (in freertos.c) */
  MX_FREERTOS_Init();
  /* Start scheduler */
  osKernelStart();

  /* We should never get here as control is now taken by the scheduler */
  /* Infinite loop */
  while (1)
  {

  }
}

void SystemClock_Config(void)
{
  RCC_OscInitTypeDef RCC_OscInitStruct = {0};
  RCC_ClkInitTypeDef RCC_ClkInitStruct = {0};
  RCC_PeriphCLKInitTypeDef PeriphClkInit = {0};

  /** Configure the main internal regulator output voltage
  */
  HAL_PWREx_ControlVoltageScaling(PWR_REGULATOR_VOLTAGE_SCALE1_BOOST);
  /** Configure LSE Drive Capability
  */
  HAL_PWR_EnableBkUpAccess();
  __HAL_RCC_LSEDRIVE_CONFIG(RCC_LSEDRIVE_LOW);
  /** Initializes the RCC Oscillators according to the specified parameters
  * in the RCC_OscInitTypeDef structure.
  */
  RCC_OscInitStruct.OscillatorType = RCC_OSCILLATORTYPE_HSI48|RCC_OSCILLATORTYPE_HSE
                              |RCC_OSCILLATORTYPE_LSE;
  RCC_OscInitStruct.HSEState = RCC_HSE_ON;
  RCC_OscInitStruct.LSEState = RCC_LSE_ON;
  RCC_OscInitStruct.HSI48State = RCC_HSI48_ON;
  RCC_OscInitStruct.PLL.PLLState = RCC_PLL_ON;
  RCC_OscInitStruct.PLL.PLLSource = RCC_PLLSOURCE_HSE;
  RCC_OscInitStruct.PLL.PLLM = RCC_PLLM_DIV2;
  RCC_OscInitStruct.PLL.PLLN = 40;
  RCC_OscInitStruct.PLL.PLLP = RCC_PLLP_DIV2;
  RCC_OscInitStruct.PLL.PLLQ = RCC_PLLQ_DIV8;
  RCC_OscInitStruct.PLL.PLLR = RCC_PLLR_DIV2;
  if (HAL_RCC_OscConfig(&RCC_OscInitStruct) != HAL_OK)
  {
    Error_Handler();
  }
  /** Initializes the CPU, AHB and APB buses clocks
  */
  RCC_ClkInitStruct.ClockType = RCC_CLOCKTYPE_HCLK|RCC_CLOCKTYPE_SYSCLK
                              |RCC_CLOCKTYPE_PCLK1|RCC_CLOCKTYPE_PCLK2;
  RCC_ClkInitStruct.SYSCLKSource = RCC_SYSCLKSOURCE_PLLCLK;
  RCC_ClkInitStruct.AHBCLKDivider = RCC_SYSCLK_DIV1;
  RCC_ClkInitStruct.APB1CLKDivider = RCC_HCLK_DIV2;
  RCC_ClkInitStruct.APB2CLKDivider = RCC_HCLK_DIV4;

  if (HAL_RCC_ClockConfig(&RCC_ClkInitStruct, FLASH_LATENCY_4) != HAL_OK)
  {
    Error_Handler();
  }
  /** Initializes the peripherals clocks
  */
  PeriphClkInit.PeriphClockSelection = RCC_PERIPHCLK_RTC|RCC_PERIPHCLK_I2C1
                              |RCC_PERIPHCLK_I2C2|RCC_PERIPHCLK_I2C3
                              |RCC_PERIPHCLK_I2C4|RCC_PERIPHCLK_USB
                              |RCC_PERIPHCLK_RNG|RCC_PERIPHCLK_ADC12
                              |RCC_PERIPHCLK_FDCAN;
  PeriphClkInit.I2c1ClockSelection = RCC_I2C1CLKSOURCE_PCLK1;
  PeriphClkInit.I2c2ClockSelection = RCC_I2C2CLKSOURCE_PCLK1;
  PeriphClkInit.I2c3ClockSelection = RCC_I2C3CLKSOURCE_PCLK1;
  PeriphClkInit.I2c4ClockSelection = RCC_I2C4CLKSOURCE_PCLK1;
  PeriphClkInit.FdcanClockSelection = RCC_FDCANCLKSOURCE_PCLK1;
  PeriphClkInit.RngClockSelection = RCC_RNGCLKSOURCE_HSI48;
  PeriphClkInit.UsbClockSelection = RCC_USBCLKSOURCE_HSI48;
  PeriphClkInit.Adc12ClockSelection = RCC_ADC12CLKSOURCE_SYSCLK;
  PeriphClkInit.RTCClockSelection = RCC_RTCCLKSOURCE_LSE;
  if (HAL_RCCEx_PeriphCLKConfig(&PeriphClkInit) != HAL_OK)
  {
    Error_Handler();
  }
}

void Error_Handler(void)
{
}

/************************ (C) COPYRIGHT STMicroelectronics *****END OF FILE****/

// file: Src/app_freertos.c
/* USER CODE BEGIN Header */
/**
  ******************************************************************************
  * File Name          : app_freertos.c
  * Description        : Code for freertos applications
  ******************************************************************************
  * @attention
  *
  * <h2><center>&copy; Copyright (c) 2020 STMicroelectronics.
  * All rights reserved.</center></h2>
  *
  * This software component is licensed by ST under Ultimate Liberty license
  * SLA0044, the "License"; You may not use this file except in compliance with
  * the License. You may obtain a copy of the License at:
  *                             www.st.com/SLA0044
  *
  ******************************************************************************
  */
/* USER CODE END Header */

#include "FreeRTOS.h"
#include "task.h"
#include "main.h"
#include "cmsis_os.h"

/* USER CODE BEGIN Includes */
#include <stdlib.h> /* abs() */
#include <stdio.h>
#include "usbd_vcom.h"
#include "console.h"
#include "leds.h"
#include "analog.h"
#include "queue.h"
#include "utilities.h"
#include "../Drivers/piezo/piezo.h"
#include "../Drivers/piezo/tables/generated/delta_8192_table.c"
#include "../Drivers/piezo/tables/generated/delta_1024_table.c"
#include "../Drivers/piezo/tables/generated/rhomb_8192_table.c"
#include "../Drivers/encoder/qe_encoder.h"
#include "../Drivers/encoder/lr17_encoder.h"

/* USER CODE END Includes */

/* Definitions for Main */
osThreadId_t MainHandle;
const osThreadAttr_t Main_attributes = {
  .name = "Main",
  .priority = (osPriority_t) osPriorityNormal,
  .stack_size = 1024 * 4
};

void MainTask(void *argument);

void MX_FREERTOS_Init(void); /* (MISRA C 2004 rule 8.1) */

void MX_FREERTOS_Init(void) {

  /* Create the thread(s) */
  /* creation of Main */
  MainHandle = osThreadNew(MainTask, NULL, &Main_attributes);

}

/* USER CODE BEGIN Header_MainTask */
/**
  * @brief  Function implementing the Main thread.
  * @param  argument: Not used
  * @retval None
  */

#define printf coprintf
#define UI_STAT_DOWNSAMPLING 5

typedef struct {
    int ival;
    int mot;
    enum {
        ACT_GO,
        ACT_FREE,
        ACT_BRAKE,
        ACT_MAX,
        ACT_MIN,
        ACT_STEP,
        ACT_RECOVER,
    } action;
} demo_cmd_t;

uint32_t led_red[] = {LED_RED0, LED_RED1, LED_RED2};
QueueHandle_t cmd_queue  = NULL ;
void CmdTask(void *argument)
{
    char cobuf[64];
    const char *coptr;
    char ch;
    demo_cmd_t cmd;
    long tmpsl;

    while (1) {
        coLockedEditString(portMAX_DELAY, cobuf, sizeof(cobuf));
        coprintf("\r");
        printf("\033[K");
        coptr = cobuf;

        if (!atosl(&coptr, &tmpsl) || (tmpsl > 3))
            continue;
        ch = toupper(skipblank(&coptr));
        coptr++;
        cmd.mot = tmpsl;
        switch ((int)ch) {
        case 'G':
            cmd.action = ACT_GO;
            break;
        case 'F':
            cmd.action = ACT_FREE;
            break;
        case 'B':
            cmd.action = ACT_BRAKE;
            break;
        case 'X':
            cmd.action = ACT_MAX;
            if (!atosl(&coptr, &tmpsl) || (tmpsl > 1000))
                continue;
            cmd.ival = tmpsl;
            break;
        case 'N':
            cmd.action = ACT_MIN;
            if (!atosl(&coptr, &tmpsl) || (tmpsl > 1000)) {
                continue;
            }
            cmd.ival = tmpsl;
            break;
        case 'S':
            cmd.action = ACT_STEP;
            if (!atosl(&coptr, &tmpsl) || (tmpsl > 100))
                continue;
            cmd.ival = tmpsl;
            break;
        case 'R':
            cmd.action = ACT_RECOVER;
            break;

        default:
            continue;
        }

        xQueueSendToFront(cmd_queue, &cmd, 0);
    }
}

/* USER CODE END Header_MainTask */
void MainTask(void *argument)
{
  /* USER CODE BEGIN MainTask */
    demo_cmd_t cmd;
    int i;
    piezoMotorCfg_t cfg1, cfg2, cfg3;
    qe_encoder_cfg_t qe_cfg[2] = {
        {.htim = &htim2},
        {.htim = &htim5}
    };
    qe_encoder_t qe[2];
    int qe_val[2];
    int lr17_val;
    int ui_stat_counter = UI_STAT_DOWNSAMPLING;
    piezoMotorState_t state[3];
    int vel[3] = {0, 0, 0};
    int vel_min[3] = {0, 0, 0};
    int vel_max[3] = {100, 100, 100};
    int delta[3] = {10, 10, 10};

    if (VCOM_OK != vcomInit()) {
        while(1) {
            LED_TOGGLE(LED_ORANGEPORT, LED_ORANGE0);
            osDelay(50);
        }
    }

    LED_ON(LED_ORANGEPORT, LED_ORANGE0);

    vcomRxChar();
    cmd_queue = xQueueCreate(1, sizeof(demo_cmd_t));
    if (NULL == cmd_queue) {
        while(1) {
            LED_TOGGLE(LED_ORANGEPORT, LED_ORANGE0);
            osDelay(100);
        }
    }

#ifndef DEBUG_SPI
    if (pdPASS != xTaskCreate(CmdTask, "CmdTask",
                              configMINIMAL_STACK_SIZE, NULL,
                              osPriorityNormal, NULL)) {
        while(1) {
            LED_TOGGLE(LED_ORANGEPORT, LED_ORANGE0);
            osDelay(1000);
        }
    }
#endif
    printf("Cmd are in form '<mot> <cmd> [<par>]' Where 0 =< mot <= 2; cmd is a char\n");
    printf("cmds: Recover, miNimum, maXimum, Step, Go, Freewheel, Brake\n");

    analogInit();
    lr17_encoder_init();

    for (i = 0; i < 2; i++)
             qe_encoder_init(&qe[i], &qe_cfg[i]);

    cfg1.phaseTable = delta_1024;
    cfg2.phaseTable = delta_8192;
    cfg3.phaseTable = rhomb_8192;

    cfg1.phaseTableLen = 1024;
    cfg2.phaseTableLen = 8192;
    cfg3.phaseTableLen = 8192;

    if (HAL_OK != piezoInit(&cfg1, &cfg2, &cfg3)) {
	    printf("ERROR: piezo init failure\n");
	    while(1);
    }

    vel[0] = 0;

    while (1) {
        if (pdPASS == xQueueReceive(cmd_queue, &cmd, 0)) {
            switch (cmd.action) {
            case ACT_RECOVER:
                piezoOvercurrentClear(cmd.mot);
                break;
            case ACT_GO:
                piezoSetMode(cmd.mot, PIEZO_NORMAL);
                break;
            case ACT_FREE:
                piezoSetMode(cmd.mot, PIEZO_FREEWHEELING);
                break;
            case ACT_BRAKE:
                piezoSetMode(cmd.mot, PIEZO_BRAKE);
                break;
            case ACT_MAX:
                vel_max[cmd.mot] = cmd.ival;
                break;
            case ACT_MIN:
                vel_min[cmd.mot] = cmd.ival;
                break;
            case ACT_STEP:
                delta[cmd.mot] = cmd.ival;
                break;
            break;
            }
        }

        for (i = 0; i < 3; i++) {
            piezoSetStepFrequency(i, vel[i]);
            vel[i] += delta[i];
            if (vel[i] > vel_max[i]) {
                vel[i] = vel_max[i];
                delta[i] = -abs(delta[i]);
            }

            if (vel[i] < vel_min[i]) {
                vel[i] = vel_min[i];
                delta[i] = abs(delta[i]);
            }
        }
        osDelay(100);

        for (i = 0; i < 3; i++) {
            piezoGetState(i, &state[i]);
            if (state[i] == STATE_OVERCURRENT) {
                LED_ON(LED_REDPORT, led_red[i]);
            } else {
                LED_OFF(LED_REDPORT, led_red[i]);
            }
        }

        if (ui_stat_counter == 1)
            lr17_encoder_acquire(NULL, NULL);
        if (!ui_stat_counter--) {
            ui_stat_counter = UI_STAT_DOWNSAMPLING;
            for (i = 0; i < 2; i++)
                qe_encoder_get(&qe[i], &qe_val[i]);
            lr17_encoder_get(&lr17_val);
            printf("\033[s");
            printf("\033[5;0H");
            printf("encoders: QE1: %d, QE2: %d, ABS: %d\n",
                   qe_val[0], qe_val[1], lr17_val);

            printf("protection: %d %d %d\n",
                   state[0] == STATE_OVERCURRENT,
                   state[1] == STATE_OVERCURRENT,
                   state[2] == STATE_OVERCURRENT);
            printf("VREFINT = %5u mV, VIN = %5u mV, CIN = %5u mA, VPP = %5u mV, VCC = %5u mV\n",
                     analogGetVref_mV(), analogGetVin_mV(),
                     analogGetIin_mA(), analogGetVpp_mV(), analogGetVcc_mV());
            printf("\033[u");

        }
    }
  /* USER CODE END MainTask */
}

/************************ (C) COPYRIGHT STMicroelectronics *****END OF FILE****/
